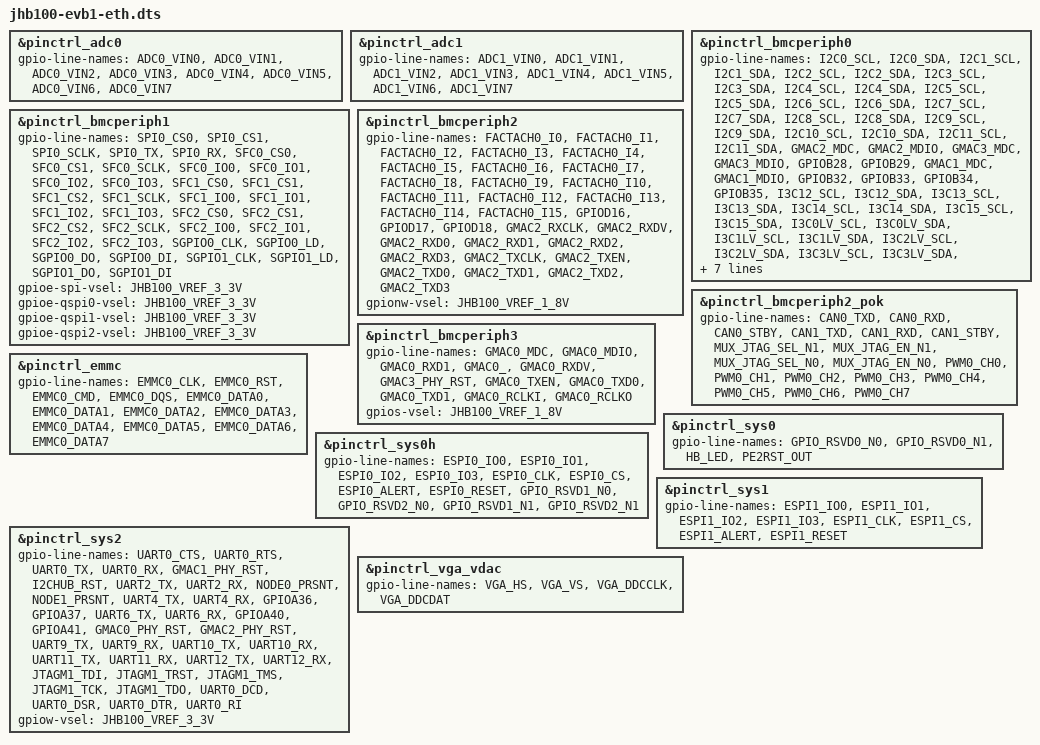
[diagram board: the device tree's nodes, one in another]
// SPDX-License-Identifier: GPL-2.0 OR MIT
/*
 * Copyright (c) 2025 StarFive Technology Co., Ltd.
 */

#include "jhb100-evb1.dtsi"
#include "jhb100-evb1-sfc0-flash.dtsi"
#include "jhb100-evb1-ethernet.dtsi"
#include "jhb100-evb1-peripheral.dtsi"

&pinctrl_adc0 {
	gpio-line-names =
		"ADC0_VIN0", "ADC0_VIN1", "ADC0_VIN2", "ADC0_VIN3",		/* GPIOG0-3 */
		"ADC0_VIN4", "ADC0_VIN5", "ADC0_VIN6", "ADC0_VIN7";		/* GPIOG4-7 */
};

&pinctrl_adc1 {
	gpio-line-names =
		"ADC1_VIN0", "ADC1_VIN1", "ADC1_VIN2", "ADC1_VIN3",		/* GPIOH0-3 */
		"ADC1_VIN4", "ADC1_VIN5", "ADC1_VIN6", "ADC1_VIN7";		/* GPIOH4-7 */
};

&pinctrl_bmcperiph0 {
	gpio-line-names =
		"I2C0_SCL", "I2C0_SDA", "I2C1_SCL", "I2C1_SDA",			/* GPIOB0-3 */
		"I2C2_SCL", "I2C2_SDA", "I2C3_SCL", "I2C3_SDA",			/* GPIOB4-7 */
		"I2C4_SCL", "I2C4_SDA", "I2C5_SCL", "I2C5_SDA",			/* GPIOB8-11 */
		"I2C6_SCL", "I2C6_SDA", "I2C7_SCL", "I2C7_SDA",			/* GPIOB12-15 */
		"I2C8_SCL", "I2C8_SDA", "I2C9_SCL", "I2C9_SDA",			/* GPIOB16-19 */
		"I2C10_SCL", "I2C10_SDA", "I2C11_SCL", "I2C11_SDA",		/* GPIOB20-23 */
		"GMAC2_MDC", "GMAC2_MDIO", "GMAC3_MDC", "GMAC3_MDIO",		/* GPIOB24-27 */
		"GPIOB28", "GPIOB29", "GMAC1_MDC", "GMAC1_MDIO",		/* GPIOB28-31 */
		"GPIOB32", "GPIOB33", "GPIOB34", "GPIOB35",			/* GPIOB32-35 */
		"I3C12_SCL", "I3C12_SDA", "I3C13_SCL", "I3C13_SDA",		/* GPIOB36-39 */
		"I3C14_SCL", "I3C14_SDA", "I3C15_SCL", "I3C15_SDA",		/* GPIOB40-43 */
		"I3C0LV_SCL", "I3C0LV_SDA", "I3C1LV_SCL", "I3C1LV_SDA",		/* GPIOB44-47 */
		"I3C2LV_SCL", "I3C2LV_SDA", "I3C3LV_SCL", "I3C3LV_SDA",		/* GPIOB48-51 */
		"I3C4LV_SCL", "I3C4LV_SDA", "I3C5LV_SCL", "I3C5LV_SDA",		/* GPIOB52-55 */
		"I3C6LV_SCL", "I3C6LV_SDA", "I3C7LV_SCL", "I3C7LV_SDA";		/* GPIOB56-59 */

	gpioe-i3c0-vsel = <JHB100_VREF_1_8V>; /* VREF for GPIOB8-11, 32-33 */
	gpioe-i3c1-vsel = <JHB100_VREF_1_8V>; /* VREF for GPIOB12-15, 34-35 */
	gpioe-i3c2-vsel = <JHB100_VREF_1_8V>; /* VREF for GPIOB16-23 */
	gpioe-i3c4-vsel = <JHB100_VREF_1_8V>; /* VREF for GPIOB36-43 */
};

&pinctrl_bmcperiph1 {
	gpio-line-names =
		"SPI0_CS0", "SPI0_CS1", "SPI0_SCLK", "SPI0_TX",		/* GPIOC0-3 */
		"SPI0_RX", "SFC0_CS0", "SFC0_CS1", "SFC0_SCLK",		/* GPIOC4-7 */
		"SFC0_IO0", "SFC0_IO1", "SFC0_IO2", "SFC0_IO3",		/* GPIOC8-11 */
		"SFC1_CS0", "SFC1_CS1", "SFC1_CS2", "SFC1_SCLK",	/* GPIOC12-15 */
		"SFC1_IO0", "SFC1_IO1", "SFC1_IO2", "SFC1_IO3",		/* GPIOC16-19 */
		"SFC2_CS0", "SFC2_CS1", "SFC2_CS2", "SFC2_SCLK",	/* GPIOC20-23 */
		"SFC2_IO0", "SFC2_IO1", "SFC2_IO2", "SFC2_IO3",		/* GPIOC24-27 */
		"SGPIO0_CLK", "SGPIO0_LD", "SGPIO0_DO", "SGPIO0_DI",	/* GPIOC28-31 */
		"SGPIO1_CLK", "SGPIO1_LD", "SGPIO1_DO", "SGPIO1_DI";	/* GPIOC32-35 */

	gpioe-spi-vsel = <JHB100_VREF_3_3V>; /* VREF for GPIOC0-4 */
	gpioe-qspi0-vsel = <JHB100_VREF_3_3V>; /* VREF for GPIOC5-11 */
	gpioe-qspi1-vsel = <JHB100_VREF_3_3V>; /* VREF for GPIOC12-19 */
	gpioe-qspi2-vsel = <JHB100_VREF_3_3V>; /* VREF for GPIOC20-27 */
};

&pinctrl_bmcperiph2 {
	gpio-line-names =
		"FACTACH0_I0", "FACTACH0_I1", "FACTACH0_I2", "FACTACH0_I3",	/* GPIOD0-3 */
		"FACTACH0_I4", "FACTACH0_I5", "FACTACH0_I6", "FACTACH0_I7",	/* GPIOD4-7 */
		"FACTACH0_I8", "FACTACH0_I9", "FACTACH0_I10", "FACTACH0_I11",	/* GPIOD8-11 */
		"FACTACH0_I12", "FACTACH0_I13", "FACTACH0_I14", "FACTACH0_I15",	/* GPIOD12-15 */
		"GPIOD16", "GPIOD17", "GPIOD18", "GMAC2_RXCLK",			/* GPIOD16-19 */
		"GMAC2_RXDV", "GMAC2_RXD0", "GMAC2_RXD1", "GMAC2_RXD2",		/* GPIOD20-23 */
		"GMAC2_RXD3", "GMAC2_TXCLK", "GMAC2_TXEN", "GMAC2_TXD0",	/* GPIOD24-27 */
		"GMAC2_TXD1", "GMAC2_TXD2", "GMAC2_TXD3";			/* GPIOD28-30 */

	gpionw-vsel = <JHB100_VREF_1_8V>; /* VREF for GPIOD19-30 */
};

&pinctrl_bmcperiph2_pok {
	gpio-line-names =
		"CAN0_TXD", "CAN0_RXD", "CAN0_STBY", "CAN1_TXD",		/* GPIOD31-34 */
		"CAN1_RXD", "CAN1_STBY", "MUX_JTAG_SEL_N1", "MUX_JTAG_EN_N1",	/* GPIOD35-38 */
		"MUX_JTAG_SEL_N0", "MUX_JTAG_EN_N0", "PWM0_CH0", "PWM0_CH1",	/* GPIOD39-42 */
		"PWM0_CH2", "PWM0_CH3", "PWM0_CH4", "PWM0_CH5",			/* GPIOD43-46 */
		"PWM0_CH6", "PWM0_CH7";						/* GPIOD47-48 */
};

&pinctrl_bmcperiph3 {
	gpio-line-names =
		"GMAC0_MDC", "GMAC0_MDIO", "GMAC0_RXD1", "GMAC0_",		/* GPIOE0-3 */
		"GMAC0_RXDV", "GMAC3_PHY_RST", "GMAC0_TXEN", "GMAC0_TXD0",	/* GPIOE4-7 */
		"GMAC0_TXD1", "GMAC0_RCLKI", "GMAC0_RCLKO";			/* GPIOE8-11 */

	gpios-vsel = <JHB100_VREF_1_8V>; /* VREF for GPIOE0-10 */
};

&pinctrl_emmc {
	gpio-line-names =
		"EMMC0_CLK", "EMMC0_RST", "EMMC0_CMD", "EMMC0_DQS",		/* GPIOF0-3 */
		"EMMC0_DATA0", "EMMC0_DATA1", "EMMC0_DATA2", "EMMC0_DATA3",	/* GPIOF4-7 */
		"EMMC0_DATA4", "EMMC0_DATA5", "EMMC0_DATA6", "EMMC0_DATA7";	/* GPIOF8-11 */
};

&pinctrl_sys0 {
	gpio-line-names =
		"GPIO_RSVD0_N0", "GPIO_RSVD0_N1", "HB_LED", "PE2RST_OUT";	/* GPIOA0-3 */
};

&pinctrl_sys0h {
	gpio-line-names =
		"ESPI0_IO0", "ESPI0_IO1", "ESPI0_IO2", "ESPI0_IO3",		/* GPIOA4-7 */
		"ESPI0_CLK", "ESPI0_CS", "ESPI0_ALERT", "ESPI0_RESET",		/* GPIOA8-11 */
		"GPIO_RSVD1_N0", "GPIO_RSVD2_N0",				/* GPIOA12-13 */
		"GPIO_RSVD1_N1", "GPIO_RSVD2_N1";				/* GPIOA14-15 */
};

&pinctrl_sys1 {
	gpio-line-names =
		"ESPI1_IO0", "ESPI1_IO1", "ESPI1_IO2", "ESPI1_IO3",		/* GPIOA16-19 */
		"ESPI1_CLK", "ESPI1_CS", "ESPI1_ALERT", "ESPI1_RESET";		/* GPIOA20-23 */
};

&pinctrl_sys2 {
	gpio-line-names =
		"UART0_CTS", "UART0_RTS", "UART0_TX", "UART0_RX",		/* GPIOA24-27 */
		"GMAC1_PHY_RST", "I2CHUB_RST", "UART2_TX", "UART2_RX",		/* GPIOA28-31 */
		"NODE0_PRSNT", "NODE1_PRSNT", "UART4_TX", "UART4_RX",		/* GPIOA32-35 */
		"GPIOA36", "GPIOA37", "UART6_TX", "UART6_RX",			/* GPIOA36-39 */
		"GPIOA40", "GPIOA41", "GMAC0_PHY_RST", "GMAC2_PHY_RST",		/* GPIOA40-43 */
		"UART9_TX", "UART9_RX", "UART10_TX", "UART10_RX",		/* GPIOA44-47 */
		"UART11_TX", "UART11_RX", "UART12_TX", "UART12_RX",		/* GPIOA48-51 */
		"JTAGM1_TDI", "JTAGM1_TRST", "JTAGM1_TMS", "JTAGM1_TCK",	/* GPIOA52-55 */
		"JTAGM1_TDO", "UART0_DCD", "UART0_DSR", "UART0_DTR",		/* GPIOA56-59 */
		"UART0_RI";							/* GPIOA60 */

	gpiow-vsel = <JHB100_VREF_3_3V>; /* VREF for GPIOA36-43 */
};

&pinctrl_vga_vdac {
	gpio-line-names =
		"VGA_HS", "VGA_VS", "VGA_DDCCLK", "VGA_DDCDAT";		/* GPIOI0-3 */
};
